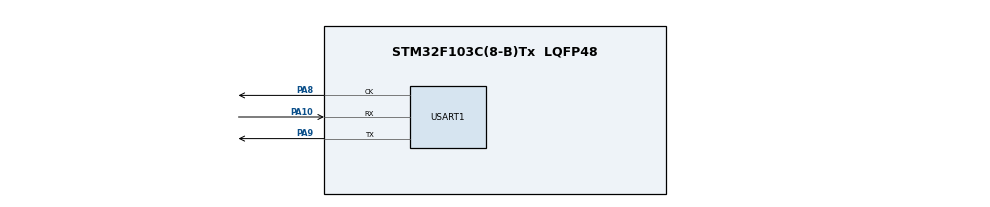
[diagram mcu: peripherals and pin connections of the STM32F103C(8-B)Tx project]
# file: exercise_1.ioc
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Mcu.Family=STM32F1
Mcu.Name=STM32F103C(8-B)Tx
Mcu.Package=LQFP48
NVIC.PriorityGroup=NVIC_PRIORITYGROUP_4
NVIC.TIM2_IRQn=true\:15\:0\:false\:false\:true\:false\:true\:true
NVIC.TimeBase=TIM2_IRQn
NVIC.TimeBaseIP=TIM2
PA10.Mode=Synchronous
PA10.Signal=USART1_RX
PA8.Mode=Synchronous
PA8.Signal=USART1_CK
PA9.Mode=Synchronous
PA9.Signal=USART1_TX
ProjectManager.HeapSize=0x200
ProjectManager.StackSize=0x400
ProjectManager.TargetToolchain=STM32CubeIDE
RCC.APB1Freq_Value=8000000
RCC.APB2Freq_Value=8000000
USART1.VirtualMode=VM_SYNC
VP_SYS_VS_tim2.Mode=TIM2
board=custom

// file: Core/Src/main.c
/* USER CODE BEGIN Header */
/**
  ******************************************************************************
  * @file           : main.c
  * @brief          : Main program body
  ******************************************************************************
  * @attention
  *
  * Copyright (c) 2024 STMicroelectronics.
  * All rights reserved.
  *
  * This software is licensed under terms that can be found in the LICENSE file
  * in the root directory of this software component.
  * If no LICENSE file comes with this software, it is provided AS-IS.
  *
  ******************************************************************************
  */
/* USER CODE END Header */
#include "main.h"

/* USER CODE BEGIN Includes */
#include "FreeRTOS.h"
#include "task.h"
/* USER CODE END Includes */

/* USER CODE BEGIN PD */
#define DWT_CTRL  *((volatile uint32_t *)0xE0001000)
/* USER CODE END PD */

USART_HandleTypeDef husart1;

void SystemClock_Config(void);
static void MX_GPIO_Init(void);
static void MX_USART1_Init(void);
/* USER CODE BEGIN PFP */

void Task1_handler(void* parameter)
{

	while(1)
	{
		(void)HAL_USART_Transmit(&husart1, "This is task 2 handler \n", 25, 22000U);
		taskYIELD();
	}
}

void Task2_handler(void* parameter)
{

	while(1)
	{

		(void)HAL_USART_Transmit(&husart1, "This is task 1 handler \n", 25, 22000U);
		taskYIELD();
	}
}

/* USER CODE END PFP */

int main(void)
{
  /* USER CODE BEGIN 1 */
	TaskHandle_t task1_Handle = NULL,task2_Handle = NULL;
	BaseType_t task1_Returned,task2_Returned;
  /* USER CODE END 1 */

  /* MCU Configuration--------------------------------------------------------*/

  /* Reset of all peripherals, Initializes the Flash interface and the Systick. */
  HAL_Init();

  /* Configure the system clock */
  SystemClock_Config();

  /* Initialize all configured peripherals */
  MX_GPIO_Init();
  MX_USART1_Init();

  /* USER CODE BEGIN 2 */

  DWT_CTRL |=1;

  SEGGER_SYSVIEW_Conf();
  SEGGER_SYSVIEW_Start();

  task1_Returned = xTaskCreate(  Task1_handler, "Task_1", 30, NULL, 1, &task1_Handle );
  task2_Returned = xTaskCreate(  Task2_handler, "Task_2", 30, NULL, 1, &task2_Handle );
  vTaskStartScheduler();
  /* USER CODE END 2 */

  /* Infinite loop */
  while (1)
  {

  }
}

void SystemClock_Config(void)
{
  RCC_OscInitTypeDef RCC_OscInitStruct = {0};
  RCC_ClkInitTypeDef RCC_ClkInitStruct = {0};

  /** Initializes the RCC Oscillators according to the specified parameters
  * in the RCC_OscInitTypeDef structure.
  */
  RCC_OscInitStruct.OscillatorType = RCC_OSCILLATORTYPE_HSI;
  RCC_OscInitStruct.HSIState = RCC_HSI_ON;
  RCC_OscInitStruct.HSICalibrationValue = RCC_HSICALIBRATION_DEFAULT;
  RCC_OscInitStruct.PLL.PLLState = RCC_PLL_NONE;
  if (HAL_RCC_OscConfig(&RCC_OscInitStruct) != HAL_OK)
  {
    Error_Handler();
  }

  /** Initializes the CPU, AHB and APB buses clocks
  */
  RCC_ClkInitStruct.ClockType = RCC_CLOCKTYPE_HCLK|RCC_CLOCKTYPE_SYSCLK
                              |RCC_CLOCKTYPE_PCLK1|RCC_CLOCKTYPE_PCLK2;
  RCC_ClkInitStruct.SYSCLKSource = RCC_SYSCLKSOURCE_HSI;
  RCC_ClkInitStruct.AHBCLKDivider = RCC_SYSCLK_DIV1;
  RCC_ClkInitStruct.APB1CLKDivider = RCC_HCLK_DIV1;
  RCC_ClkInitStruct.APB2CLKDivider = RCC_HCLK_DIV1;

  if (HAL_RCC_ClockConfig(&RCC_ClkInitStruct, FLASH_LATENCY_0) != HAL_OK)
  {
    Error_Handler();
  }
}

static void MX_USART1_Init(void)
{

  husart1.Instance = USART1;
  husart1.Init.BaudRate = 115200;
  husart1.Init.WordLength = USART_WORDLENGTH_8B;
  husart1.Init.StopBits = USART_STOPBITS_1;
  husart1.Init.Parity = USART_PARITY_NONE;
  husart1.Init.Mode = USART_MODE_TX_RX;
  husart1.Init.CLKPolarity = USART_POLARITY_LOW;
  husart1.Init.CLKPhase = USART_PHASE_1EDGE;
  husart1.Init.CLKLastBit = USART_LASTBIT_DISABLE;
  if (HAL_USART_Init(&husart1) != HAL_OK)
  {
    Error_Handler();
  }

}

static void MX_GPIO_Init(void)
{

  /* GPIO Ports Clock Enable */
  __HAL_RCC_GPIOA_CLK_ENABLE();

}

void HAL_TIM_PeriodElapsedCallback(TIM_HandleTypeDef *htim)
{
  if (htim->Instance == TIM2) {
    HAL_IncTick();
  }
}

void Error_Handler(void)
{
  __disable_irq();
  while (1)
  {
  }
}
